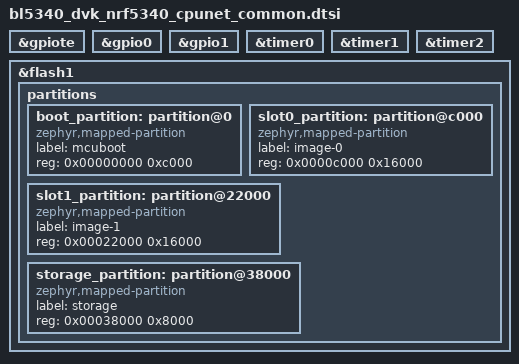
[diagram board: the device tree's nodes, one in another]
/*
 * Copyright (c) 2021-2023 Laird Connectivity
 *
 * SPDX-License-Identifier: Apache-2.0
 */

#include <nordic/nrf5340_cpunet_qkaa.dtsi>

&gpiote {
	status = "okay";
};

&gpio0 {
	status = "okay";
};

&gpio1 {
	status = "okay";
};

&timer0 {
	status = "okay";
};

&timer1 {
	status = "okay";
};

&timer2 {
	status = "okay";
};

&flash1 {
	partitions {
		#address-cells = <1>;
		#size-cells = <1>;
		ranges;

		boot_partition: partition@0 {
			compatible = "zephyr,mapped-partition";
			label = "mcuboot";
			reg = <0x00000000 0xc000>;
		};

		slot0_partition: partition@c000 {
			compatible = "zephyr,mapped-partition";
			label = "image-0";
			reg = <0x0000c000 0x16000>;
		};

		slot1_partition: partition@22000 {
			compatible = "zephyr,mapped-partition";
			label = "image-1";
			reg = <0x00022000 0x16000>;
		};

		storage_partition: partition@38000 {
			compatible = "zephyr,mapped-partition";
			label = "storage";
			reg = <0x00038000 0x8000>;
		};
	};
};

/* Include shared RAM configuration file */
#include "bl5340_dvk_nrf5340_shared_sram_planning_conf.dtsi"
